# qmss_desc register map
Vendor: Texas Instruments
Peripheral module from a debugger description file (folder Keystone2).
Registers are 32-bit, read-write, no defined reset value unless marked. A register's access mark holds for its fields unless they carry their own. Offsets are as the file gives them; lines under a group give offsets from that group; [hi:lo] are bit positions; {n}, {i} and the like mark numbered series; 'fields as' and 'values as' point back to an identical list; <NAME> marks a mode.

## QM_2_DESC
0x00 MEMORY_REGION_BASE_ADDRESS_REG — (1 of 64, stride 16)
  [31:0] regR_base — This field contains the base address of the memory region R.
0x04 MEMORY_REGION_START_INDEX_REG — (1 of 64, stride 16)
  [18:0] start_index — This field indicates where in linking RAM does the descriptor linking information corresponding to memory region R starts.
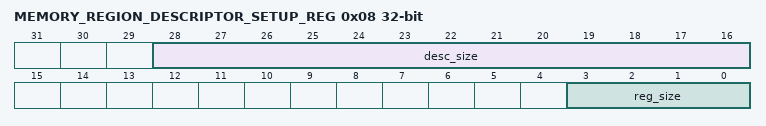
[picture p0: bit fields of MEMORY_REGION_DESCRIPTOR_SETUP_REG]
0x08 MEMORY_REGION_DESCRIPTOR_SETUP_REG — (1 of 64, stride 16)
  [28:16] desc_size — This field indicates the size of each descriptor in this memory region. The value programmed is the multipler minus one that needs to be applied to 16 to get the actual descriptor size.
  [3:0] reg_size — This field indicates the size of the memory region (in terms of number of descriptors). It is an encoded value that specifies region size as 2^\[5+reg_size\] number of descriptors.
